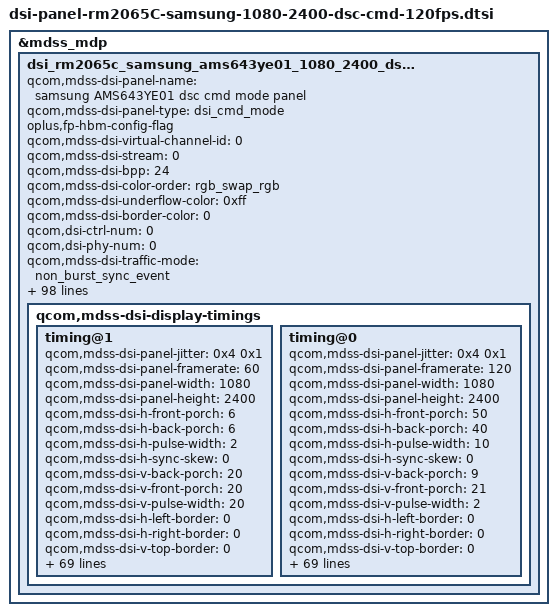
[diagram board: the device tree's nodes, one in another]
&mdss_mdp {
	dsi_rm2065c_samsung_ams643ye01_1080_2400_dsc_cmd: qcom,mdss_dsi_rm2065c_samsung_ams643ye01_1080_2400_dsc_cmd {
		qcom,mdss-dsi-panel-name = "samsung AMS643YE01 dsc cmd mode panel";
		qcom,mdss-dsi-panel-type = "dsi_cmd_mode";
		oplus,fp-hbm-config-flag;
		qcom,mdss-dsi-virtual-channel-id = <0>;
		qcom,mdss-dsi-stream = <0>;
		qcom,mdss-dsi-bpp = <24>;
		qcom,mdss-dsi-color-order = "rgb_swap_rgb";
		qcom,mdss-dsi-underflow-color = <0xff>;
		qcom,mdss-dsi-border-color = <0>;
		qcom,dsi-ctrl-num = <0>;
		qcom,dsi-phy-num = <0>;
		qcom,mdss-dsi-traffic-mode = "non_burst_sync_event";
		qcom,mdss-dsi-lane-map = "lane_map_0123";
		qcom,mdss-dsi-bllp-eof-power-mode;
		qcom,mdss-dsi-bllp-power-mode;
		qcom,mdss-dsi-lane-0-state;
		qcom,mdss-dsi-lane-1-state;
		qcom,mdss-dsi-lane-2-state;
		qcom,mdss-dsi-lane-3-state;
		qcom,mdss-dsi-dma-trigger = "trigger_sw";
		qcom,mdss-dsi-mdp-trigger = "none";
		qcom,mdss-dsi-reset-sequence = <1 10>, <0 10>, <1 10>;

		qcom,mdss-dsi-te-pin-select = <1>;
		qcom,mdss-dsi-te-dcs-command = <1>;
		qcom,mdss-dsi-te-check-enable;
		qcom,mdss-dsi-te-using-te-pin;
		qcom,mdss-dsi-lp11-init;
		qcom,mdss-dsi-wr-mem-start = <0x2c>;
		qcom,mdss-dsi-wr-mem-continue = <0x3c>;
		qcom,mdss-dsi-panel-hdr-enabled;
		qcom,mdss-dsi-panel-hdr-color-primaries = <15000 15500 34000
			16000 13250 34500 7500 3000>;
		qcom,mdss-dsi-panel-peak-brightness = <4300000>;
		qcom,mdss-dsi-panel-blackness-level = <1023>;
		qcom,mdss-pan-physical-width-dimension = <67>;
		qcom,mdss-pan-physical-height-dimension = <149>;
		qcom,esd-check-enabled;
		qcom,mdss-dsi-panel-status-check-mode = "reg_read";
		qcom,mdss-dsi-panel-status-command = [06 01 00 01 05 00 02 0A 00
							06 01 00 01 05 00 02 03 00
							06 01 00 01 05 00 02 05 00];
		qcom,mdss-dsi-panel-status-command-state = "dsi_hs_mode";
		qcom,mdss-dsi-panel-status-value = <0x9f 0x01 0x00>;
		qcom,mdss-dsi-panel-status-read-length = <1 1 1>;
		oplus,esd-err-flag-check-enabled;
		//oplus,esd-err-flag-gpio = <&tlmm 84 0>;
		oplus,esd-err-trigger-polarity = <0>;
		qcom,dynamic-mode-switch-enabled;
		qcom,dynamic-mode-switch-type = "dynamic-resolution-switch-immediate";
		qcom,mdss-dsi-display-timings {
			timing@1 {
				qcom,mdss-dsi-panel-jitter = <0x4 0x1>;
				//qcom,mdss-mdp-transfer-time-us = <10000>;
				//qcom,mdss-dsi-panel-clockrate = <800000000>;
				qcom,mdss-dsi-panel-framerate = <60>;
				qcom,mdss-dsi-panel-width = <1080>;
				qcom,mdss-dsi-panel-height = <2400>;
				qcom,mdss-dsi-h-front-porch = <6>;
				qcom,mdss-dsi-h-back-porch = <6>;
				qcom,mdss-dsi-h-pulse-width = <2>;
				qcom,mdss-dsi-h-sync-skew = <0>;
				qcom,mdss-dsi-v-back-porch = <20>;
				qcom,mdss-dsi-v-front-porch = <20>;
				qcom,mdss-dsi-v-pulse-width = <20>;
				qcom,mdss-dsi-h-left-border = <0>;
				qcom,mdss-dsi-h-right-border = <0>;
				qcom,mdss-dsi-v-top-border = <0>;
				qcom,mdss-dsi-v-bottom-border = <0>;
				oplus,fod-on-vblank = <0>;
				oplus,fod-off-vblank = <4>;
				qcom,mdss-dsi-timing-switch-command = [
					39 01 00 00 00 00 03 F0 5A 5A
					39 01 00 00 00 00 03 60 00 00
					15 01 00 00 00 00 02 F7 0F
					39 01 00 00 11 00 03 F0 A5 A5
					/*OSC 400 + 180.3*/
					39 01 00 00 00 00 03 F0 5A 5A
					39 01 00 00 00 00 03 FC 5A 5A
					39 01 00 00 00 00 03 B0 66 C5
					39 01 00 00 00 00 03 C5 00 8C
					39 01 00 00 00 00 03 B0 2A C5
					39 01 00 00 00 00 05 C5 0D 10 80 45
					39 01 00 00 00 00 03 B0 2E C5
					39 01 00 00 00 00 03 C5 6F 39
					39 01 00 00 00 00 03 F0 A5 A5
					39 01 00 00 00 00 03 FC A5 A5
				];
				qcom,mdss-dsi-on-command = [
					/* PPS Setting */
					39 01 00 00 00 00 81 9E
					11 00 00 89 30 80 09 60
					04 38 00 1E 02 1C 02 1C
					02 00 02 0E 00 20 02 E3
					00 07 00 0C 03 50 03 64
					18 00 10 F0 03 0C 20 00
					06 0B 0B 33 0E 1C 2A 38
					46 54 62 69 70 77 79 7B
					7D 7E 01 02 01 00 09 40
					09 BE 19 FC 19 FA 19 F8
					1A 38 1A 78 1A B6 2A F6
					2B 34 2B 74 3B 74 6B F4
					00 00 00 00 00 00 00 00
					00 00 00 00 00 00 00 00
					00 00 00 00 00 00 00 00
					00 00 00 00 00 00 00 00
					00 00 00 00 00 00 00 00
					15 01 00 00 00 00 02 C2 14			/* MIC OFF */
					15 01 00 00 00 00 02 9D 01			/* DSC enable */
					/*Err FG SET*/
					39 01 00 00 00 00 03 F0 5A 5A
					15 01 00 00 00 00 02 E5 15
					39 01 00 00 00 00 04 ED 44 4C 20
					39 01 00 00 00 00 03 F0 A5 A5
					/* Sleep Out(11h) */
					05 01 00 00 78 00 01 11
					//clk mask
					39 01 00 00 00 00 03 F0 5A 5A
					39 01 00 00 00 00 03 B0 2E F2
					15 01 00 00 00 00 02 F2 55
					39 01 00 00 00 00 03 F0 A5 A5
					/* CASET/PASET Setting */
					39 01 00 00 00 00 05 2A 00 00 04 37			/* CASET */
					39 01 00 00 00 00 05 2B 00 00 09 5F			/* PASET */
					/*FQ CON Setting*/
					39 01 00 00 00 00 03 F0 5A 5A
					39 01 00 00 00 00 03 B0 27 F2
					15 01 00 00 00 00 02 F2 00
					39 01 00 00 00 00 03 F0 A5 A5
					/*Power ctrl*/
					//39 01 00 00 00 00 03 F0 5A 5A
					//39 01 00 00 00 00 03 B0 09 B5
					//39 01 00 00 00 00 03 B5 00 00
					//39 01 00 00 00 00 03 F0 A5 A5
					/* SEED CRC Setting */
					39 01 00 00 00 00 03 F0 5A 5A
					39 01 00 00 00 00 02 5D 86
					/* SEED CRC ON */
					39 01 00 00 00 00 02 62 00
					/* SEED CRC DCI-P3 */
					39 01 00 00 00 00 03 B0 2B 62
					39 01 00 00 00 00 16 62 E0 00 06 13 D3 03 07 0B EE 16 FA E2 F7 00 E4 E9 E6 03 FF FF FF
					39 01 00 00 00 00 03 F0 A5 A5
					/*DBV 2.2*/
					//39 01 00 00 00 00 03 F0 5A 5A
					//39 01 00 00 00 00 03 B0 02 90
					//15 01 00 00 00 00 02 90 18
					//39 01 00 00 00 00 03 B0 28 F2
					//15 01 00 00 00 00 02 F2 CE
					//39 01 00 00 00 00 04 B0 01 5C 65
					//39 01 00 00 00 00 0D 65 04 4C 0B 41 0E 17 41 FC 2B 83 B8 7F
					//39 01 00 00 00 00 04 B0 01 7D 65
					//39 01 00 00 00 00 16 65 0B 41 0E 17 41 BC 1F C2 62 2B 83 02 34 43 80 3B 84 06 4B A7 FF
					//39 01 00 00 00 00 04 B0 02 47 65
					//15 01 00 00 00 00 02 65 05
					//39 01 00 00 00 00 04 B0 00 28 F2
					//15 01 00 00 00 00 02 F2 C6
					//39 01 00 00 00 00 03 F0 A5 A5
					/*FPS CHANGE*/
					39 01 00 00 00 00 03 F0 5A 5A
					39 01 00 00 00 00 03 60 00 00		/* 60Hz */
					15 01 00 00 00 00 02 F7 0F
					39 01 00 00 00 00 03 F0 A5 A5
					/*OSC*/
					//39 01 00 00 00 00 03 F0 5A 5A
					//39 01 00 00 00 00 03 FC 5A 5A
					//39 01 00 00 00 00 03 B0 66 C5
					//39 01 00 00 00 00 03 C5 00 8C
					//39 01 00 00 00 00 03 B0 2A C5
					//39 01 00 00 00 00 05 C5 0D 10 80 45
					//39 01 00 00 00 00 03 B0 2E C5
					//39 01 00 00 00 00 03 C5 73 64
					//39 01 00 00 00 00 03 F0 A5 A5
					//39 01 00 00 00 00 03 FC A5 A5
					/* Common Setting */
					15 01 00 00 00 00 02 35 00					/* TE On(Vsync) */
				];
				qcom,mdss-dsi-off-command= [
					05 01 00 00 0C 00 01 28
					05 01 00 00 78 00 01 10];
				qcom,mdss-dsi-post-on-backlight = [
					/* Display On */
					05 01 00 00 00 00 01 29
				];
				qcom,mdss-dsi-hbm-on-command = [
					/* DLY OFF */
					39 01 00 00 00 00 03 F0 5A 5A
					39 01 00 00 00 00 03 B0 91 63
					15 01 00 00 00 00 02 63 20
					39 01 00 00 00 00 03 F0 A5 A5
					/* HBM Mode ON */
					39 01 00 00 00 00 02 53 E0
					39 01 00 00 00 00 03 51 0A A0
					/* FOD MODE ON */
					39 01 00 00 00 00 03 F0 5A 5A
					39 01 00 00 00 00 03 8F 02 7E
					39 01 00 00 00 00 03 F0 A5 A5
					/* DLY ON */
					39 01 00 00 00 00 03 F0 5A 5A
					39 01 00 00 00 00 03 B0 91 63
					15 01 00 00 00 00 02 63 30
					39 01 00 00 00 00 03 F0 A5 A5
				];
				qcom,mdss-dsi-normal-hbm-on-command = [
					/* HBM Mode ON */
					39 01 00 00 00 00 02 53 E0
					39 01 00 00 00 00 03 51 0A E0
				];
				qcom,mdss-dsi-hbm-off-command = [
					/* FOD MODE OFF */
					39 01 00 00 00 00 03 F0 5A 5A
					39 01 00 00 00 00 03 8F 02 72
					39 01 00 00 00 00 03 F0 A5 A5
					/*HBM OFF*/
					15 01 00 00 00 00 02 53 20
				];
				qcom,mdss-dsi-aod-hbm-on-command = [
					39 01 00 00 00 00 03 F0 5A 5A
					15 01 00 00 00 00 02 91 02
					15 01 00 00 00 00 02 53 20
					39 01 00 00 00 00 03 F0 A5 A5
					39 01 00 00 00 00 02 53 E0
				];
				qcom,mdss-dsi-aod-hbm-off-command = [
					39 01 00 00 00 00 03 F0 5A 5A
					15 01 00 00 00 00 02 91 01
					15 01 00 00 00 00 02 53 24
					15 01 00 00 00 00 02 BB 1D
					39 01 00 00 00 00 03 F0 A5 A5
					15 01 00 00 00 00 02 53 20
				];
				qcom,mdss-dsi-aod-high-mode-command = [
					/* AOD 50nit */
					39 01 00 00 00 00 03 F0 5A 5A
					15 01 00 00 00 00 02 91 01
					15 01 00 00 00 00 02 53 24
					15 01 00 00 00 00 02 BB 1D
					39 01 00 00 00 00 03 F0 A5 A5
				];
				qcom,mdss-dsi-aod-low-mode-command = [
					/* AOD 10nit */
					39 01 00 00 00 00 03 F0 5A 5A
					15 01 00 00 00 00 02 91 01
					15 01 00 00 00 00 02 53 25
					15 01 00 00 00 00 02 BB 1D
					39 01 00 00 00 00 03 F0 A5 A5
				];
				qcom,mdss-dsi-lp1-command = [
					/*AOD on */
					39 01 00 00 00 00 03 F0 5A 5A
					15 01 00 00 00 00 02 91 01
					15 01 00 00 00 00 02 53 24
					15 01 00 00 00 00 02 BB 1D
					39 01 00 00 00 00 03 F0 A5 A5
				];
				qcom,mdss-dsi-nolp-command = [
					/* FOD MODE OFF */
					39 01 00 00 00 00 03 F0 5A 5A
					39 01 00 00 00 00 03 8F 02 72
					39 01 00 00 00 00 03 F0 A5 A5
					/* AOD off to normal*/
					39 01 00 00 00 00 03 F0 5A 5A
					15 01 00 00 00 00 02 91 02
					15 01 00 00 00 00 02 53 20
					39 01 00 00 00 00 03 F0 A5 A5
				];
				qcom,mdss-dsi-seed-off-command = [
					/* CRC OFF */
					39 01 00 00 00 00 03 F0 5A 5A
					15 01 00 00 00 00 02 5D 00
					15 01 00 00 00 00 02 62 01
					39 01 00 00 00 00 03 F0 A5 A5
				];
				qcom,mdss-dsi-seed-0-command = [
					/* SEED CRC Setting */
					39 01 00 00 00 00 03 F0 5A 5A
					39 01 00 00 00 00 02 5D 86		/*DCI P3*/
					/* SEED CRC ON */
					39 01 00 00 00 00 02 62 00
					/* SEED CRC DCI-P3 */
					39 01 00 00 00 00 03 B0 2B 62
					39 01 00 00 00 00 16 62 E0 00 06 13 D3 03 07 0B EE 16 FA E2 F7 00 E4 E9 E6 03 FF FF FF
					39 01 00 00 00 00 03 F0 A5 A5
				];
				qcom,mdss-dsi-seed-1-command = [
					/* SEED CRC Setting */
					39 01 00 00 00 00 03 F0 5A 5A
					39 01 00 00 00 00 02 5D 06		/* SRGB */
					/* SEED CRC ON */
					39 01 00 00 00 00 02 62 00
					/* SEED CRC Adobe */
					39 01 00 00 00 00 03 B0 01 62
					39 01 00 00 00 00 16 62 B0 02 06 3F D3 15 05 09 B0 48 F2 DC C4 07 C8 E9 E9 1D FD F5 E1
					39 01 00 00 00 00 03 F0 A5 A5
				];
				qcom,mdss-dsi-seed-2-command = [
					/* SEED CRC Setting */
					39 01 00 00 00 00 03 F0 5A 5A
					39 01 00 00 00 00 02 5D 46		/* ADOBE */
					/* SEED CRC ON */
					39 01 00 00 00 00 02 62 00
					/* SEED CRC Adobe */
					39 01 00 00 00 00 03 B0 16 62
					39 01 00 00 00 00 16 62 E0 00 06 00 FF 00 00 00 FF 00 FF FF FF 00 FF FF FF 00 FF FF FF
					39 01 00 00 00 00 03 F0 A5 A5
				];
				qcom,mdss-dsi-hbm-enter-switch-command = [
					15 00 00 00 00 00 02 53 E0
				];
				qcom,mdss-dsi-hbm-exit-switch-command = [
					15 00 00 00 00 00 02 53 20
					39 01 00 00 11 00 03 51 07 FF
				];
				qcom,mdss-dsi-osc-clk-mode0-command = [
					/*OSC 400 + 180.3*/
					39 01 00 00 00 00 03 F0 5A 5A
					39 01 00 00 00 00 03 FC 5A 5A
					39 01 00 00 00 00 03 B0 66 C5
					39 01 00 00 00 00 03 C5 00 8C
					39 01 00 00 00 00 03 B0 2A C5
					39 01 00 00 00 00 05 C5 0D 10 80 45
					39 01 00 00 00 00 03 B0 2E C5
					39 01 00 00 00 00 03 C5 73 64
					39 01 00 00 00 00 03 F0 A5 A5
					39 01 00 00 00 00 03 FC A5 A5
				];
				qcom,mdss-dsi-osc-clk-mode1-command = [
					/*OSC 400 + 182.3*/
					39 01 00 00 00 00 03 F0 5A 5A
					39 01 00 00 00 00 03 FC 5A 5A
					39 01 00 00 00 00 03 B0 66 C5
					39 01 00 00 00 00 03 C5 00 8C
					39 01 00 00 00 00 03 B0 2A C5
					39 01 00 00 00 00 05 C5 0D 10 80 45
					39 01 00 00 00 00 03 B0 2E C5
					39 01 00 00 00 00 03 C5 74 AC
					39 01 00 00 00 00 03 F0 A5 A5
					39 01 00 00 00 00 03 FC A5 A5
				];

				qcom,mdss-dsi-timing-switch-command-state = "dsi_hs_mode";
				qcom,mdss-dsi-on-command-state = "dsi_lp_mode";
				qcom,mdss-dsi-off-command-state = "dsi_hs_mode";
				qcom,mdss-dsi-hbm-on-command-state = "dsi_hs_mode";
				qcom,mdss-dsi-hbm-off-command-state = "dsi_hs_mode";
				qcom,mdss-dsi-osc-clk-mode0-command-state = "dsi_hs_mode";
				qcom,mdss-dsi-osc-clk-mode1-command-state = "dsi_hs_mode";
				qcom,mdss-dsi-h-sync-pulse = <0>;
				qcom,compression-mode = "dsc";
				qcom,mdss-dsc-slice-height = <30>;
				qcom,mdss-dsc-slice-width = <540>;
				qcom,mdss-dsc-slice-per-pkt = <2>;
				qcom,mdss-dsc-bit-per-component = <8>;
				qcom,mdss-dsc-bit-per-pixel = <8>;
				qcom,mdss-dsc-block-prediction-enable;
			};

			timing@0 {
				qcom,mdss-dsi-panel-jitter = <0x4 0x1>;
				//qcom,mdss-mdp-transfer-time-us = <8000>;
				//qcom,mdss-dsi-panel-clockrate = <800000000>;
				qcom,mdss-dsi-panel-framerate = <120>;
				qcom,mdss-dsi-panel-width = <1080>;
				qcom,mdss-dsi-panel-height = <2400>;
				qcom,mdss-dsi-h-front-porch = <50>;
				qcom,mdss-dsi-h-back-porch = <40>;
				qcom,mdss-dsi-h-pulse-width = <10>;
				qcom,mdss-dsi-h-sync-skew = <0>;
				qcom,mdss-dsi-v-back-porch = <9>;
				qcom,mdss-dsi-v-front-porch = <21>;
				qcom,mdss-dsi-v-pulse-width = <2>;
				qcom,mdss-dsi-h-left-border = <0>;
				qcom,mdss-dsi-h-right-border = <0>;
				qcom,mdss-dsi-v-top-border = <0>;
				qcom,mdss-dsi-v-bottom-border = <0>;
				oplus,fod-on-vblank = <0>;
				oplus,fod-off-vblank = <4>;
				qcom,mdss-dsi-timing-switch-command = [
					39 01 00 00 00 00 03 F0 5A 5A
					39 01 00 00 00 00 03 60 08 00
					15 01 00 00 00 00 02 F7 0F
					39 01 00 00 00 00 03 F0 A5 A5
					/*OSC 400 + 180.3*/
					39 01 00 00 00 00 03 F0 5A 5A
					39 01 00 00 00 00 03 FC 5A 5A
					39 01 00 00 00 00 03 B0 66 C5
					39 01 00 00 00 00 03 C5 00 8C
					39 01 00 00 00 00 03 B0 2A C5
					39 01 00 00 00 00 05 C5 0D 10 80 45
					39 01 00 00 00 00 03 B0 2E C5
					39 01 00 00 00 00 03 C5 6F 39
					39 01 00 00 00 00 03 F0 A5 A5
					39 01 00 00 00 00 03 FC A5 A5
				];
				qcom,mdss-dsi-on-command = [
					/* PPS Setting */
					39 01 00 00 00 00 81 9E
					11 00 00 89 30 80 09 60
					04 38 00 1E 02 1C 02 1C
					02 00 02 0E 00 20 02 E3
					00 07 00 0C 03 50 03 64
					18 00 10 F0 03 0C 20 00
					06 0B 0B 33 0E 1C 2A 38
					46 54 62 69 70 77 79 7B
					7D 7E 01 02 01 00 09 40
					09 BE 19 FC 19 FA 19 F8
					1A 38 1A 78 1A B6 2A F6
					2B 34 2B 74 3B 74 6B F4
					00 00 00 00 00 00 00 00
					00 00 00 00 00 00 00 00
					00 00 00 00 00 00 00 00
					00 00 00 00 00 00 00 00
					00 00 00 00 00 00 00 00
					15 01 00 00 00 00 02 C2 14			/* MIC OFF */
					15 01 00 00 00 00 02 9D 01			/* DSC enable */
					/*Err FG SET*/
					39 01 00 00 00 00 03 F0 5A 5A
					15 01 00 00 00 00 02 E5 15
					39 01 00 00 00 00 04 ED 44 4C 20
					39 01 00 00 00 00 03 F0 A5 A5
					/* Sleep Out(11h) */
					05 01 00 00 78 00 01 11
					//clk mask
					39 01 00 00 00 00 03 F0 5A 5A
					39 01 00 00 00 00 03 B0 2E F2
					15 01 00 00 00 00 02 F2 55
					39 01 00 00 00 00 03 F0 A5 A5
					/* Common Setting */
					15 01 00 00 00 00 02 35 00					/* TE On(Vsync) */
					/* CASET/PASET Setting */
					39 01 00 00 00 00 05 2A 00 00 04 37			/* CASET */
					39 01 00 00 00 00 05 2B 00 00 09 5F			/* PASET */
					/*FQ CON Setting*/
					39 01 00 00 00 00 03 F0 5A 5A
					39 01 00 00 00 00 03 B0 27 F2
					15 01 00 00 00 00 02 F2 00
					39 01 00 00 00 00 03 F0 A5 A5
					/*Power ctrl*/
					//39 01 00 00 00 00 03 F0 5A 5A
					//39 01 00 00 00 00 03 B0 09 B5
					//39 01 00 00 00 00 03 B5 00 00
					//39 01 00 00 00 00 03 F0 A5 A5
					/* SEED CRC Setting */
					39 01 00 00 00 00 03 F0 5A 5A
					39 01 00 00 00 00 02 5D 86
					/* SEED CRC ON */
					39 01 00 00 00 00 02 62 00
					/* SEED CRC DCI-P3 */
					39 01 00 00 00 00 03 B0 2B 62
					39 01 00 00 00 00 16 62 E0 00 06 13 D3 03 07 0B EE 16 FA E2 F7 00 E4 E9 E6 03 FF FF FF
					39 01 00 00 00 00 03 F0 A5 A5
					/*DBV 2.2*/
					//39 01 00 00 00 00 03 F0 5A 5A
					//39 01 00 00 00 00 03 B0 02 90
					//15 01 00 00 00 00 02 90 18
					//39 01 00 00 00 00 03 B0 28 F2
					//15 01 00 00 00 00 02 F2 CE
					//39 01 00 00 00 00 04 B0 01 5C 65
					//39 01 00 00 00 00 0D 65 04 4C 0B 41 0E 17 41 FC 2B 83 B8 7F
					//39 01 00 00 00 00 04 B0 01 7D 65
					//39 01 00 00 00 00 16 65 0B 41 0E 17 41 BC 1F C2 62 2B 83 02 34 43 80 3B 84 06 4B A7 FF
					//39 01 00 00 00 00 04 B0 02 47 65
					//15 01 00 00 00 00 02 65 05
					//39 01 00 00 00 00 04 B0 00 28 F2
					//15 01 00 00 00 00 02 F2 C6
					//39 01 00 00 00 00 03 F0 A5 A5
					/*FPS CHANGE*/
					39 01 00 00 00 00 03 F0 5A 5A
					39 01 00 00 00 00 03 60 08 00		/* 120Hz */
					15 01 00 00 00 00 02 F7 0F
					39 01 00 00 00 00 03 F0 A5 A5
					/*OSC*/
					//39 01 00 00 00 00 03 F0 5A 5A
					//39 01 00 00 00 00 03 FC 5A 5A
					//39 01 00 00 00 00 03 B0 66 C5
					//39 01 00 00 00 00 03 C5 00 8C
					//39 01 00 00 00 00 03 B0 2A C5
					//39 01 00 00 00 00 05 C5 0D 10 80 45
					//39 01 00 00 00 00 03 B0 2E C5
					//39 01 00 00 00 00 03 C5 73 64
					//39 01 00 00 00 00 03 F0 A5 A5
					//39 01 00 00 00 00 03 FC A5 A5
				];
				qcom,mdss-dsi-off-command= [
					05 01 00 00 0C 00 01 28
					05 01 00 00 78 00 01 10];
				qcom,mdss-dsi-post-on-backlight = [
					/* Display On */
					05 01 00 00 00 00 01 29
				];
				qcom,mdss-dsi-hbm-on-command = [
					/* DLY OFF */
					39 01 00 00 00 00 03 F0 5A 5A
					39 01 00 00 00 00 03 B0 91 63
					15 01 00 00 00 00 02 63 20
					39 01 00 00 00 00 03 F0 A5 A5
					/* HBM Mode ON */
					39 01 00 00 00 00 02 53 E0
					39 01 00 00 00 00 03 51 0A A0
					/* FOD MODE ON */
					39 01 00 00 00 00 03 F0 5A 5A
					39 01 00 00 00 00 03 8F 02 7E
					39 01 00 00 00 00 03 F0 A5 A5
					/* DLY ON */
					39 01 00 00 00 00 03 F0 5A 5A
					39 01 00 00 00 00 03 B0 91 63
					15 01 00 00 00 00 02 63 30
					39 01 00 00 00 00 03 F0 A5 A5
				];
				qcom,mdss-dsi-normal-hbm-on-command = [
					/* HBM Mode ON */
					39 01 00 00 00 00 02 53 E0
					39 01 00 00 00 00 03 51 0A E0
				];
				qcom,mdss-dsi-hbm-off-command = [
					/* FOD MODE OFF */
					39 01 00 00 00 00 03 F0 5A 5A
					39 01 00 00 00 00 03 8F 02 72
					39 01 00 00 00 00 03 F0 A5 A5
					/*HBM OFF*/
					15 01 00 00 00 00 02 53 20
				];
				qcom,mdss-dsi-aod-hbm-on-command = [
					39 01 00 00 00 00 03 F0 5A 5A
					15 01 00 00 00 00 02 91 02
					15 01 00 00 00 00 02 53 20
					39 01 00 00 00 00 03 F0 A5 A5
					39 01 00 00 00 00 02 53 E0
				];
				qcom,mdss-dsi-aod-hbm-off-command = [
					39 01 00 00 00 00 03 F0 5A 5A
					15 01 00 00 00 00 02 91 01
					15 01 00 00 00 00 02 53 24
					15 01 00 00 00 00 02 BB 1D
					39 01 00 00 00 00 03 F0 A5 A5
					15 01 00 00 00 00 02 53 20
				];
				qcom,mdss-dsi-aod-high-mode-command = [
					/* AOD 50nit */
					39 01 00 00 00 00 03 F0 5A 5A
					15 01 00 00 00 00 02 91 01
					15 01 00 00 00 00 02 53 24
					15 01 00 00 00 00 02 BB 1D
					39 01 00 00 00 00 03 F0 A5 A5
				];
				qcom,mdss-dsi-aod-low-mode-command = [
					/* AOD 10nit */
					39 01 00 00 00 00 03 F0 5A 5A
					15 01 00 00 00 00 02 91 01
					15 01 00 00 00 00 02 53 25
					15 01 00 00 00 00 02 BB 1D
					39 01 00 00 00 00 03 F0 A5 A5
				];
				qcom,mdss-dsi-lp1-command = [
					/*AOD on */
					39 01 00 00 00 00 03 F0 5A 5A
					15 01 00 00 00 00 02 91 01
					15 01 00 00 00 00 02 53 24
					15 01 00 00 00 00 02 BB 1D
					39 01 00 00 00 00 03 F0 A5 A5
				];
				qcom,mdss-dsi-nolp-command = [
					/* FOD MODE OFF */
					39 01 00 00 00 00 03 F0 5A 5A
					39 01 00 00 00 00 03 8F 02 72
					39 01 00 00 00 00 03 F0 A5 A5
					/* AOD off to normal*/
					39 01 00 00 00 00 03 F0 5A 5A
					15 01 00 00 00 00 02 91 02
					15 01 00 00 00 00 02 53 20
					39 01 00 00 00 00 03 F0 A5 A5
				];
				qcom,mdss-dsi-seed-off-command = [
					/* CRC OFF */
					39 01 00 00 00 00 03 F0 5A 5A
					15 01 00 00 00 00 02 5D 00
					15 01 00 00 00 00 02 62 01
					39 01 00 00 00 00 03 F0 A5 A5
				];
				qcom,mdss-dsi-seed-0-command = [
					/* SEED CRC Setting */
					39 01 00 00 00 00 03 F0 5A 5A
					39 01 00 00 00 00 02 5D 86
					/* SEED CRC ON */
					39 01 00 00 00 00 02 62 00
					/* SEED CRC DCI-P3 */
					39 01 00 00 00 00 03 B0 2B 62
					39 01 00 00 00 00 16 62 E0 00 06 13 D3 03 07 0B EE 16 FA E2 F7 00 E4 E9 E6 03 FF FF FF
					39 01 00 00 00 00 03 F0 A5 A5
				];
				qcom,mdss-dsi-seed-1-command = [
					/* SEED CRC Setting */
					39 01 00 00 00 00 03 F0 5A 5A
					39 01 00 00 00 00 02 5D 06		/* SRGB */
					/* SEED CRC ON */
					39 01 00 00 00 00 02 62 00
					/* SEED CRC Adobe */
					39 01 00 00 00 00 03 B0 01 62
					39 01 00 00 00 00 16 62 B0 02 06 3F D3 15 05 09 B0 48 F2 DC C4 07 C8 E9 E9 1D FD F5 E1
					39 01 00 00 00 00 03 F0 A5 A5
				];
				qcom,mdss-dsi-seed-2-command = [
					/* SEED CRC Setting */
					39 01 00 00 00 00 03 F0 5A 5A
					39 01 00 00 00 00 02 5D 46		/* ADOBE */
					/* SEED CRC ON */
					39 01 00 00 00 00 02 62 00
					/* SEED CRC Adobe */
					39 01 00 00 00 00 03 B0 16 62
					39 01 00 00 00 00 16 62 E0 00 06 00 FF 00 00 00 FF 00 FF FF FF 00 FF FF FF 00 FF FF FF
					39 01 00 00 00 00 03 F0 A5 A5
				];
				qcom,mdss-dsi-hbm-enter-switch-command = [
					15 00 00 00 00 00 02 53 E0
				];
				qcom,mdss-dsi-hbm-exit-switch-command = [
					15 00 00 00 00 00 02 53 20
					39 01 00 00 11 00 03 51 07 FF
				];
				qcom,mdss-dsi-osc-clk-mode0-command = [
					/*OSC 400 + 180.3*/
					39 01 00 00 00 00 03 F0 5A 5A
					39 01 00 00 00 00 03 FC 5A 5A
					39 01 00 00 00 00 03 B0 66 C5
					39 01 00 00 00 00 03 C5 00 8C
					39 01 00 00 00 00 03 B0 2A C5
					39 01 00 00 00 00 05 C5 0D 10 80 45
					39 01 00 00 00 00 03 B0 2E C5
					39 01 00 00 00 00 03 C5 6F 39
					39 01 00 00 00 00 03 F0 A5 A5
					39 01 00 00 00 00 03 FC A5 A5
				];
				qcom,mdss-dsi-osc-clk-mode1-command = [
					/*OSC 400 + 182.3*/
					39 01 00 00 00 00 03 F0 5A 5A
					39 01 00 00 00 00 03 FC 5A 5A
					39 01 00 00 00 00 03 B0 66 C5
					39 01 00 00 00 00 03 C5 00 8C
					39 01 00 00 00 00 03 B0 2A C5
					39 01 00 00 00 00 05 C5 0D 10 80 45
					39 01 00 00 00 00 03 B0 2E C5
					39 01 00 00 00 00 03 C5 70 74
					39 01 00 00 00 00 03 F0 A5 A5
					39 01 00 00 00 00 03 FC A5 A5
				];

				qcom,mdss-dsi-timing-switch-command-state = "dsi_hs_mode";
				qcom,mdss-dsi-on-command-state = "dsi_lp_mode";
				qcom,mdss-dsi-off-command-state = "dsi_hs_mode";
				qcom,mdss-dsi-hbm-on-command-state = "dsi_hs_mode";
				qcom,mdss-dsi-hbm-off-command-state = "dsi_hs_mode";
				qcom,mdss-dsi-osc-clk-mode0-command-state = "dsi_hs_mode";
				qcom,mdss-dsi-osc-clk-mode1-command-state = "dsi_hs_mode";
				qcom,mdss-dsi-h-sync-pulse = <0>;
				qcom,compression-mode = "dsc";
				qcom,mdss-dsc-slice-height = <30>;
				qcom,mdss-dsc-slice-width = <540>;
				qcom,mdss-dsc-slice-per-pkt = <2>;
				qcom,mdss-dsc-bit-per-component = <8>;
				qcom,mdss-dsc-bit-per-pixel = <8>;
				qcom,mdss-dsc-block-prediction-enable;
			};
		};
	};
};

&dsi_rm2065c_samsung_ams643ye01_1080_2400_dsc_cmd {
	qcom,panel-supply-entries = <&dsi_panel_pwr_supply_vout>;
	qcom,mdss-dsi-bl-pmic-control-type = "bl_ctrl_dcs";
	qcom,mdss-dsi-bl-min-level = <1>;
	qcom,mdss-dsi-bl-normal-max-level = <2047>;
	qcom,mdss-dsi-bl-max-level = <2784>;
	qcom,mdss-brightness-normal-max-level = <2047>;
	qcom,mdss-brightness-max-level = <2784>;
	qcom,mdss-brightness-default-level = <400>;
	qcom,platform-te-gpio = <&tlmm 10 0>;
	qcom,platform-reset-gpio = <&pm8150l_gpios 3 0>;
	oplus,mdss-dsi-vendor-name = "AMS643YE01";
	oplus,mdss-dsi-manufacture = "samsung1024";
	qcom,ulps-enabled;
	qcom,suspend-ulps-enabled;
	qcom,dsi-dyn-clk-enable;
	qcom,dsi-dyn-clk-list = <830000000 800000000>;
	qcom,dsi-select-clocks = "mux_byte_clk0", "mux_pixel_clk0",
						"src_byte_clk0", "src_pixel_clk0",
						"shadow_byte_clk0", "shadow_pixel_clk0";
	oplus,osc-support;
	oplus,raw-backlight;
	oplus,mdss-dsi-osc-clk-mode0-rate = <180300>;
	oplus,mdss-dsi-osc-clk-mode1-rate = <182300>;
	qcom,mdss-dsi-dc-backlight-level = <520>;
	oplus,bl_interpolate_nosub;
	oplus,dsi-fod-brightness = <0 0xff>,
			<2 0xf2>,
			<4 0xed>,
			<6 0xec>,
			<8 0xea>,
			<10 0xe9>,
			<20 0xe4>,
			<40 0xdc>,
			<60 0xd4>,
			<90 0xca>,
			<140 0xc0>,
			<200 0xb4>,
			<300 0xa4>,
			<450 0x93>,
			<600 0x81>,
			<750 0x77>,
			<900 0x69>,
			<1050 0x60>,
			<1200 0x54>,
			<1400 0x49>,
			<1600 0x3c>,
			<1800 0x32>,
			<2047 0x24>;

	oplus,dsi-dc-brightness = <0 0xff>,
			<2 0xFC>,
			<4 0xF9>,
			<6 0xF9>,
			<8 0xF8>,
			<10 0xF7>,
			<15 0xF6>,
			<20 0xF4>,
			<30 0xF0>,
			<40 0xEB>,
			<50 0xE6>,
			<60 0xE1>,
			<70 0xDD>,
			<80 0xD8>,
			<100 0xCF>,
			<120 0xC5>,
			<150 0xB9>,
			<200 0xA2>,
			<250 0x8C>,
			<300 0x76>,
			<350 0x5B>,
			<400 0x44>,
			<450 0x2C>,
			<500 0x0D>,
			<520 0x00>;

	oplus,dsi-brightness-remapping = <4    4>,
			<5    5>,
			<6    6>,
			<7    7>,
			<10   10>,
			<244  19>,
			<431  67>,
			<550  114>,
			<645  161>,
			<725  209>,
			<797  256>,
			<860  304>,
			<919  351>,
			<974  399>,
			<1025 446>,
			<1073 494>,
			<1120 541>,
			<1163 589>,
			<1245 684>,
			<1283 732>,
			<1321 779>,
			<1357 827>,
			<1391 874>,
			<1425 922>,
			<1458 969>,
			<1491 1017>,
			<1522 1064>,
			<1582 1159>,
			<1611 1207>,
			<1640 1254>,
			<1668 1302>,
			<1695 1349>,
			<1722 1397>,
			<1748 1445>,
			<1774 1492>,
			<1800 1540>,
			<1825 1587>,
			<1850 1635>,
			<1874 1682>,
			<1898 1730>,
			<1921 1777>,
			<1944 1825>,
			<1967 1872>,
			<1990 1920>,
			<2012 1967>,
			<2034 2015>,
			<2047 2047>,
			<2784 2784>,
			<4095 4095>;

	qcom,mdss-dsi-display-timings {
		timing@0 {
			 qcom,mdss-dsi-panel-phy-timings = [00 1D 07 07 17 22 07 07 08 02 04 00 19 0C];
			 qcom,display-topology = <1 1 1>,<2 2 1>;
			 qcom,default-topology-index = <0>;
		};
		timing@1 {
			 qcom,mdss-dsi-panel-phy-timings = [00 1D 07 07 17 16 07 07 08 02 04 00 19 0C];
			 qcom,display-topology = <1 1 1>,<2 2 1>;
			 qcom,default-topology-index = <0>;
		};
	};
};
&dsi_rm2065c_samsung_ams643ye01_1080_2400_dsc_cmd {
	qcom,panel_voltage_vddi_name = "vddio";
	qcom,panel_voltage_vddi = <0 1800000 1800000 1800000>;
	qcom,panel_voltage_vddr_name = "vout";
	qcom,panel_voltage_vddr = <1 1500000 1500000 1500000>;
};
